AUTOSAR XML (schema 00049)
standard types defined: boolean, float32, sint16, uint16, uint8, boolean_CompuMethod, boolean_DataConstr, float32_DataConstr, sint16_DataConstr, uint16_DataConstr, uint8_DataConstr
package /ComponentTypes
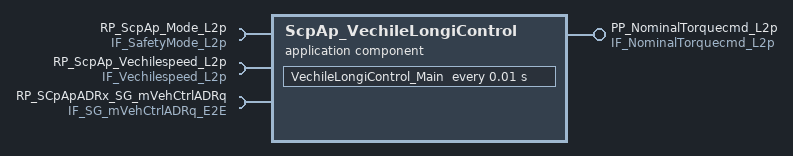
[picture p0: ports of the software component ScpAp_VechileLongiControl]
  application sw component type ScpAp_VechileLongiControl
    provide port PP_NominalTorquecmd_L2p: nonqueued-sender-com-spec{data-element=IF_NominalTorquecmd_L2p, init-value=0}, provided-interface=IF_NominalTorquecmd_L2p
    require port RP_ScpAp_Mode_L2p: nonqueued-receiver-com-spec{data-element=IF_SafetyMode_L2p, filter=data-filter-type=ALWAYS}, required-interface=IF_SafetyMode_L2p
    require port RP_ScpAp_Vechilespeed_L2p: nonqueued-receiver-com-spec{data-element=IF_Vechilespeed_L2p, filter=data-filter-type=ALWAYS}, required-interface=IF_Vechilespeed_L2p
    require port RP_SCpApADRx_SG_mVehCtrlADRq: nonqueued-receiver-com-spec{data-element=SG_mVehCtrlADRq, handle-out-of-range=DEFAULT, filter=data-filter-type=ALWAYS, init-value=fields=[AebEvent:0, AebSrcAD:0, b_High_Deceleration_Flag:0, MsgCntrmVehCtrlADRq:0, MsgCrc_mVehCtrlADRq:0, VehAccelLongCmd:0, VehDirCmd:0, VehRoadWhlAngleCmd:0, VehSpdCmd:0, CanAd78FltCod:0]}, required-interface=IF_SG_mVehCtrlADRq_E2E
    behavior ScpAp_VechileLongiControl_InternalBehavior: handle-termination-and-restart=NO-SUPPORT
      timing event TMT_VechileLongiControl_Main: start-on-event=VechileLongiControl_Main, period=0.01
      runnable VechileLongiControl_Main
        data-receive-point-by-arguments:
          access REC_RP_ScpAp_Mode_L2p_IF_SafetyMode_L2p: accessed-variable=RP_ScpAp_Mode_L2p.IF_SafetyMode_L2p
          access REC_RP_ScpAp_Vechilespeed_L2p_IF_Vechilespeed_L2p: accessed-variable=RP_ScpAp_Vechilespeed_L2p.IF_Vechilespeed_L2p
          access REC_RP_SCpApADRx_SG_mVehCtrlADRq_SG_mVehCtrlADRq: accessed-variable=RP_SCpApADRx_SG_mVehCtrlADRq.SG_mVehCtrlADRq
        data-send-points:
          access SEND_PP_NominalTorquecmd_L2p_IF_NominalTorquecmd_L2p: accessed-variable=PP_NominalTorquecmd_L2p.IF_NominalTorquecmd_L2p
  swc implementation ScpAp_VechileLongiControl_Implementation: behavior=ScpAp_VechileLongiControl_InternalBehavior
    code-descriptors:
      code Default: artifact-descriptors=autosar-engineering-object={short-label=Default, category=SWSRC}
package /DataTypes
  impl type SafetyMode_L2p_IDT: category=VALUE, base-type=BaseTypes/uint8, sw-calibration-access=READ-ONLY, compu {0=MANUAL (CompuScale), 1=AUTONOMOUS (CompuScale), 3=TELEOPS (CompuScale)}, type-emitter=RTE
  impl type SG_mVehCtrlADRq_IDT_E2E: category=STRUCTURE
    10 x element, all with category=TYPE_REFERENCE:
      AebEvent: range raw 0..1, implementation-data-type=boolean
      AebSrcAD: range raw 0..15, implementation-data-type=uint8
      b_High_Deceleration_Flag: range raw 0..1, implementation-data-type=boolean
      MsgCntrmVehCtrlADRq: range raw 0..15, implementation-data-type=uint8
      MsgCrc_mVehCtrlADRq: range raw 0..255, implementation-data-type=uint8
      VehAccelLongCmd: range raw -2048..2047, implementation-data-type=float32
      VehDirCmd: range raw 0..3, implementation-data-type=uint8
      VehRoadWhlAngleCmd: range raw -32768..32767, implementation-data-type=float32
      VehSpdCmd: range raw -2048..2047, implementation-data-type=float32
      CanAd78FltCod: implementation-data-type=uint8
package /PortInterfaces
  4 x sender receiver interface:
    IF_NominalTorquecmd_L2p: invalidation-policy{data-element=IF_NominalTorquecmd_L2p, handle-invalid=DONT-INVALIDATE}
      data IF_NominalTorquecmd_L2p: type=sint16
    IF_SafetyMode_L2p: invalidation-policy{data-element=IF_SafetyMode_L2p, handle-invalid=DONT-INVALIDATE}
      data IF_SafetyMode_L2p: type=SafetyMode_L2p_IDT
    IF_SG_mVehCtrlADRq_E2E: invalidation-policy{data-element=SG_mVehCtrlADRq, handle-invalid=DONT-INVALIDATE}
      data SG_mVehCtrlADRq: category=STRUCTURE, type=SG_mVehCtrlADRq_IDT_E2E
    IF_Vechilespeed_L2p: invalidation-policy{data-element=IF_Vechilespeed_L2p, handle-invalid=DONT-INVALIDATE}
      data IF_Vechilespeed_L2p: type=uint16
